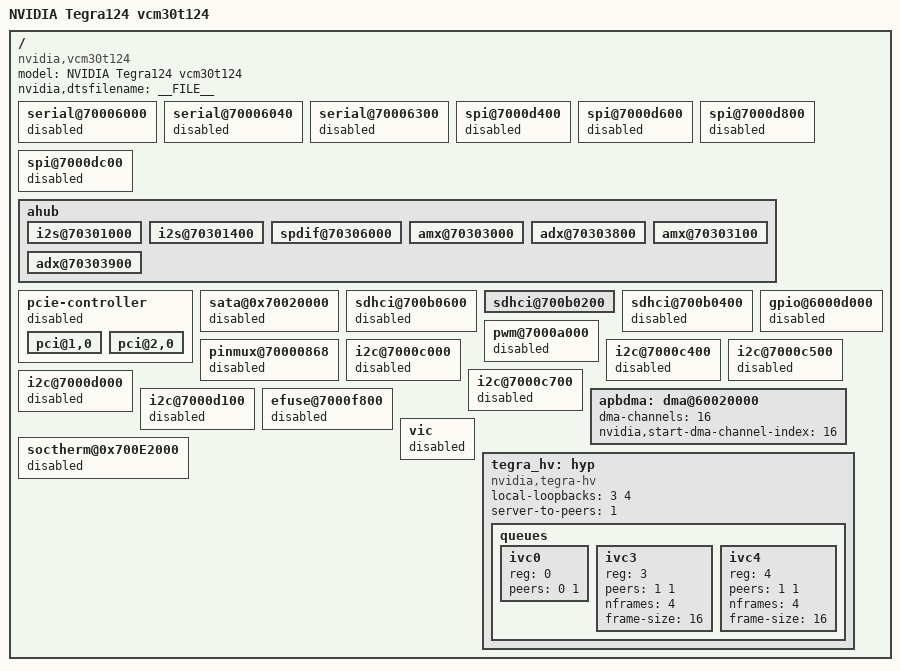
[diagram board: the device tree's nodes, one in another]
/*
 * arch/arm/boot/dts/tegra124-vcm30_t124-lk.dts
 *
 * Copyright (c) 2013-2014, NVIDIA CORPORATION.  All rights reserved.
 *
 * This program is free software; you can redistribute it and/or modify
 * it under the terms of the GNU General Public License as published by
 * the Free Software Foundation; version 2 of the License.
 *
 * This program is distributed in the hope that it will be useful, but WITHOUT
 * ANY WARRANTY; without even the implied warranty of MERCHANTABILITY or
 * FITNESS FOR A PARTICULAR PURPOSE.  See the GNU General Public License for
 * more details.
 *
 * You should have received a copy of the GNU General Public License along
 * with this program; if not, write to the Free Software Foundation, Inc.,
 * 51 Franklin Street, Fifth Floor, Boston, MA  02110-1301, USA.
 *
 */

 /dts-v1/;

#include "tegra124-vcm30_t124.dtsi"
#include <tegra124-platforms/tegra124-vcm30-t124-gpio-default.dtsi>
#include <tegra124-platforms/tegra124-vcm30-t124-pinmux.dtsi>


/ {
	model = "NVIDIA Tegra124 vcm30t124";
	compatible = "nvidia,vcm30t124", "nvidia,tegra124";
	nvidia,dtsfilename = __FILE__;
	#address-cells = <2>;
	#size-cells = <2>;

        serial@70006000 {
                status = "disabled";
        };

        serial@70006040 {
                status = "disabled";
        };

        serial@70006300 {
                status = "disabled";
        };

	spi@7000d400 {
		status = "disabled";
	};

	spi@7000d600 {
		status = "disabled";
	};

	spi@7000d800 {
		status = "disabled";
	};

	spi@7000dc00 {
		status = "disabled";
	};

	ahub {
		status = "okay";

		i2s@70301000 {
			status = "okay";
		};
		i2s@70301400 {
			status = "okay";
		};
		spdif@70306000 {
			status = "okay";
		};
		amx@70303000 {
			status = "okay";
		};
		adx@70303800 {
			status = "okay";
		};
		amx@70303100 {
			status = "okay";
		};
		adx@70303900 {
			status = "okay";
		};
	};

	pcie-controller {
		status = "disabled";

		pci@1,0 {
			status = "okay";
		};

		pci@2,0 {
			status = "okay";
		};
	};

	sata@0x70020000 {
		status = "disabled";
	};

	sdhci@700b0600 {
		status = "disabled";
	};

	sdhci@700b0200 {
		status = "okay";
	};

	sdhci@700b0400 {
		status = "disabled";
	};

	gpio@6000d000 {
		status = "disabled";
	};

	pinmux@70000868 {
		status = "disabled";
	};

	pwm@7000a000 {
		status = "disabled";
	};

	i2c@7000c000 {
		status = "disabled";
	};

	i2c@7000c400 {
		status = "disabled";
	};

	i2c@7000c500 {
		status = "disabled";
	};

	i2c@7000c700 {
		status = "disabled";
	};

	i2c@7000d000 {
		status = "disabled";
	};

	i2c@7000d100 {
		status = "disabled";
	};

	efuse@7000f800 {
		status = "disabled";
        };

	apbdma: dma@60020000 {
		dma-channels = <16>;
		nvidia,start-dma-channel-index = <16>;
		status = "okay";
	};

	vic {
		status = "disabled";
	};

	soctherm@0x700E2000 {
		status = "disabled";
	};

	tegra_hv: hyp {
		compatible = "nvidia,tegra-hv";
		status = "okay";

		local-loopbacks = <3 4>;

		server-to-peers = <1>;

		queues {
			#address-cells = <1>;
			#size-cells = <0>;

			/* guest 0 <-> guest 1 (frame based) */
			ivc0 {
				reg = <0>;
				peers = <0 1>;
			};

			/* placeholder for serial & net IVC channels */

			/* guest 1 <-> guest 1 (loop) */
			ivc3 {
				reg = <3>;
				peers = <1 1>;
				nframes = <4>;
				frame-size = <16>;
			};

			/* guest 1 <-> guest 1 (loop) */
			ivc4 {
				reg = <4>;
				peers = <1 1>;
				nframes = <4>;
				frame-size = <16>;
			};

		};
	};
};
